# FM33L0XX register map
File version: 1.0
CPU: SC000 r1p0, little endian, no MPU, no FPU, 3 interrupt priority bits
Registers are 32-bit, read-write, reset 0x0 unless marked. A register's access mark holds for its fields unless they carry their own. Offsets are from the block's base; [hi:lo] are bit positions; {n}, {i} and the like mark numbered series; 'fields as' and 'values as' point back to an identical list.

## PMU_BUF — POWER VERF MANAGEMENT UNIT
Base 0x40012818
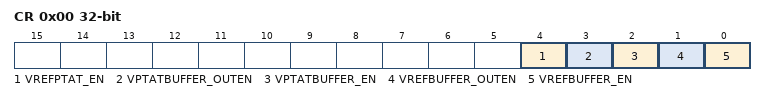
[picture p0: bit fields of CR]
0x00 CR — Buffer Control Register
  [4] VREFPTAT_EN — PTAT VREF Enable
    0=Disable (PTAT VREF Disable); 1=Enable (PTAT VREF Enable)
  [3] VPTATBUFFER_OUTEN — VPTATBUFFER OUTPUT Enable
    0=Disable (VPTATBUFFER OUTPUT Disable); 1=Enable (VPTATBUFFER OUTPUT Enable)
  [2] VPTATBUFFER_EN — VPTATBUFFER Enable
    0=Disable (VPTATBUFFER Disable); 1=Enable (VPTATBUFFER Enable)
  [1] VREFBUFFER_OUTEN — VREFBUFFER OUTPUT Enable
    0=Disable (VREFBUFFER OUTPUT Disable); 1=Enable (VREFBUFFER OUTPUT Enable)
  [0] VREFBUFFER_EN — VREFBUFFER Enable
    0=Disable (VREFBUFFER Disable); 1=Enable (VREFBUFFER Enable)

## GPIOA — GPIO PORTA
Base 0x40000C00
Same registers: GPIOB 0x40000C40, GPIOC 0x40000C80, GPIOD 0x40000CC0
0x00 INEN — input enable Register
  [15:0] INEN — input enable, pin 0-15
0x04 PUEN — pullup enable Register
  [15:0] PUEN — IO pull-up control
0x08 ODEN — open-drain Control Register
  [15:0] ODEN — open-drain control,pin0-15
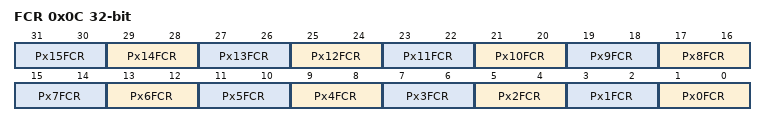
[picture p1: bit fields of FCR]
0x0C FCR — function control Register
  [all] fields
    0=INPUT (GPIO INPUT); 1=OUTPUT (GPIO OUTPUT); 2=Digital function; 3=Analog function
  [2n+1:2n] Px{n}FCR (n=0..15) — Px{n} function select
0x10 DO wo — GPIO output data register
  [15:0] DO rw — PxDO output data
0x14 DSET wo — GPIO output data set register
  [15:0] DSET — bit set high
0x18 DRESET wo — GPIO output data reset register
  [15:0] DRESET
0x1C DIN ro — Portx input data register
  [15:0] DIN — Portx input data
0x20 DFS — Portx Digital Function Select register
  [15:0] DFS ro — Portx Digital Function Select
0x24 HD
  [15:0] HD ro — Portx High Drive Enable
0x28 ANEN
  [15:0] ANEN ro — Portx Analog channel Enable

## GPIO_COMMON — GPIO_COMMON Registers
Base 0x40000D00
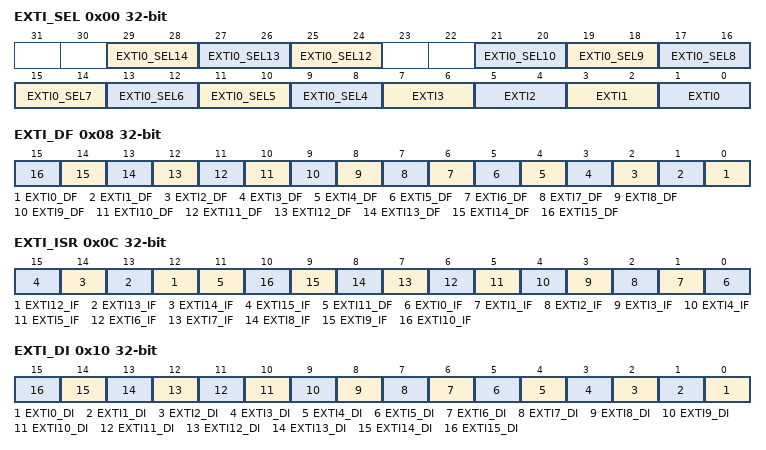
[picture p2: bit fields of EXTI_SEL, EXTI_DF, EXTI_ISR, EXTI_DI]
0x00 EXTI_SEL — GPIO EXTI Select 0
  [29:28] EXTI0_SEL14 — EXTI0[14] input pin select
    {v}=PD{v+8} (EXTI0[14]) (v=0..3)
  [27:26] EXTI0_SEL13 — EXTI0[13] input pin select
    {v}=PD{v+4} (EXTI0[13]) (v=0..3)
  [25:24] EXTI0_SEL12 — EXTI0[12] input pin select
    {v}=PD{v} (EXTI0[12]) (v=0..3)
  [21:20] EXTI0_SEL10 — EXTI0[10] input pin select
    {v}=PC{v+8} (EXTI0[10]) (v=0..3)
  [19:18] EXTI0_SEL9 — EXTI0[9] input pin select
    {v}=PC{v+4} (EXTI0[9]) (v=0..3)
  [17:16] EXTI0_SEL8 — EXTI0[8] input pin select
    {v}=PC{v} (EXTI0[8]) (v=0..3)
  [15:14] EXTI0_SEL7 — EXTI0[7] input pin select
    {v}=PB{v+12} (EXTI0[7]) (v=0..3)
  [13:12] EXTI0_SEL6 — EXTI0[6] input pin select
    {v}=PB{v+8} (EXTI0[6]) (v=0..3)
  [11:10] EXTI0_SEL5 — EXTI0[5] input pin select
    {v}=PB{v+4} (EXTI0[5]) (v=0..3)
  [9:8] EXTI0_SEL4 — EXTI0[4] input pin select
    0=PB0 (EXTI0[4]); 1=PB1 (EXTI0[4]); 2=B2 (EXTI0[4]); 3=PB3 (EXTI0[4])
  [7:6] EXTI3 — EXTI[3] input pin select
    {v}=PA{v+12} (EXTI[3]) (v=0..3)
  [5:4] EXTI2 — EXTI[2] input pin select
    {v}=PA{v+8} (EXTI[2]) (v=0..3)
  [3:2] EXTI1 — EXTI[1] input pin select
    {v}=PA{v+4} (EXTI[1]) (v=0..3)
  [1:0] EXTI0 — EXTI0[0] input pin select
    {v}=PA{v} (EXTI0[0]) (v=0..3)
0x04 EXTI_EDS reset 0xFFFFFFFF — GPIO EXTI Edge Select
  [all] fields
    0=rising; 1=falling; 2=both; 3=disable
  [2n+1:2n] EXTI{n}_EDS (n=0..14) — GPIO EXTI{n} Edge Select
  [29:28] EXTI15_EDS — GPIO EXTI15 Edge Select
0x08 EXTI_DF — GPIO EXTI Digital Filter
  [all] fields
    0=DISABLE (GPIO EXTI Digital Filter Disable); 1=enable (GPIO EXTI Digital Filter Enable)
  [n] EXTI{n}_DF (n=0..15) — GPIO EXTI Digital Filter
0x0C EXTI_ISR — GPIO EXTI IF
  [all] fields
    values as the fields of EXTI_DF
  [n] EXTI{n}_IF (n=12..15) — GPIO EXTI{n}_IF
  [11] EXTI11_DF — GPIO EXTI Digital Filter
  [n] EXTI{n}_IF (n=0..10) — GPIO EXTI{n}_IF
0x10 EXTI_DI ro — GPIO EXTI_DI
  [all] fields
    values as the fields of EXTI_DF
  [n] EXTI{n}_DI (n=0..15) — GPIO EXTI{n}_DI
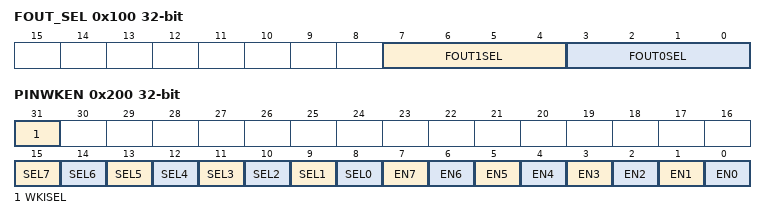
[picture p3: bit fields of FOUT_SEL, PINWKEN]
0x100 FOUT_SEL — FOUT select
  [7:4] FOUT1SEL — FOUT1 select
    0=XTLF (FOUT select XTLF); 1=RCLP (FOUT select RCLP); 2=RCHF/64 (FOUT select RCHF/64); 3=LSCLK (FOUT select LSCLK); 4=AHBCLK/64 (FOUT select AHBCLK/64); 5=RTCTM (FOUT select RTCTM); 6=PLLO/64 (FOUT select PLLO/64); 7=RTCCLK64Hz (FOUT select RTCCLK64Hz); 8=APBCLK/64 (FOUT select APBCLK/64); 9=PLLO (FOUT select PLLO); 10=RC4MPSC (FOUT select RC4MPSC); 11=RCHF; 12=XTHF/64; 13=ADCCLK/64; 14=CLK8K
  [3:0] FOUT0SEL — FOUT0 select
    values as FOUT1SEL
0x200 PINWKEN — GPIO PINWKEN
  [31] WKISEL — WKUP INTERRUPT SEL
    0=NMI; 1=#38
  [n+8] SEL{n} (n=0..7) — GPIO PIN{n}_WKSEL
    0=FALLING; 1=RISING
  [n] EN{n} (n=0..7) — GPIO PIN{n}_WKEN
    0=DISABLE; 1=ENABLE
